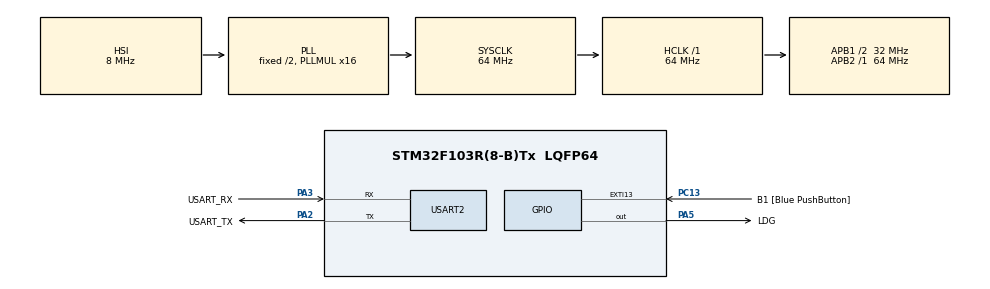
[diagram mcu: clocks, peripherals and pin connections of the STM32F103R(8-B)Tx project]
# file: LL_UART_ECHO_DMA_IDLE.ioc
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Mcu.Family=STM32F1
PC15-OSC32_OUT.Mode=LSE-External-Oscillator
NVIC.DMA1_Channel6_IRQn=true\:0\:0\:false\:false\:true\:false\:true
PA2.GPIO_PuPd=GPIO_NOPULL
Dma.USART2_TX.1.Priority=DMA_PRIORITY_LOW
PD1-OSC_OUT.Mode=HSE-External-Clock-Source
Dma.USART2_TX.1.MemInc=DMA_MINC_ENABLE
PA14.GPIO_Label=TCK
PA3.GPIO_PuPd=GPIO_NOPULL
PA2.GPIO_Speed=GPIO_SPEED_FREQ_LOW
Dma.USART2_RX.0.Direction=DMA_PERIPH_TO_MEMORY
PC13-TAMPER-RTC.Signal=GPXTI13
PD0-OSC_IN.Signal=RCC_OSC_IN
RCC.APB1CLKDivider=RCC_HCLK_DIV2
PC14-OSC32_IN.Signal=RCC_OSC32_IN
PA3.GPIO_Speed=GPIO_SPEED_FREQ_LOW
Dma.USART2_TX.1.PeriphDataAlignment=DMA_PDATAALIGN_BYTE
NVIC.USART2_IRQn=true\:0\:0\:false\:false\:true\:true\:true
RCC.SYSCLKSource=RCC_SYSCLKSOURCE_PLLCLK
ProjectManager.StackSize=0x400
Dma.USART2_RX.0.Mode=DMA_NORMAL
PD1-OSC_OUT.Signal=RCC_OSC_OUT
PA3.Mode=Asynchronous
PA13.Signal=SYS_JTMS-SWDIO
ProjectManager.TargetToolchain=STM32CubeIDE
Dma.USART2_RX.0.Priority=DMA_PRIORITY_LOW
PA3.GPIO_Mode=GPIO_MODE_AF_PP
Dma.USART2_RX.0.PeriphDataAlignment=DMA_PDATAALIGN_BYTE
RCC.HCLKFreq_Value=64000000
RCC.APB2TimFreq_Value=64000000
Dma.USART2_TX.1.Mode=DMA_NORMAL
RCC.USBFreq_Value=64000000
PC15-OSC32_OUT.Signal=RCC_OSC32_OUT
RCC.AHBFreq_Value=64000000
PD0-OSC_IN.Mode=HSE-External-Clock-Source
NVIC.EXTI15_10_IRQn=true\:0\:0\:false\:false\:true\:true\:true
PA5.Signal=GPIO_Output
Dma.USART2_TX.1.PeriphInc=DMA_PINC_DISABLE
board=NUCLEO-F103RB
RCC.RTCClockSelection=RCC_RTCCLKSOURCE_LSE
PC13-TAMPER-RTC.GPIO_Label=B1 [Blue PushButton]
RCC.PLLMUL=RCC_PLL_MUL16
Dma.USART2_TX.1.Direction=DMA_MEMORY_TO_PERIPH
RCC.APB2Freq_Value=64000000
Dma.USART2_RX.0.MemDataAlignment=DMA_MDATAALIGN_BYTE
PC14-OSC32_IN.Mode=LSE-External-Oscillator
PA5.GPIO_ModeDefaultOutputPP=GPIO_MODE_OUTPUT_PP
PA14.Mode=Serial_Wire
Dma.USART2_TX.1.Instance=DMA1_Channel7
PA5.GPIO_PuPd=GPIO_NOPULL
Dma.USART2_RX.0.Instance=DMA1_Channel6
PA13.Mode=Serial_Wire
Mcu.Name=STM32F103R(8-B)Tx
Dma.USART2_RX.0.MemInc=DMA_MINC_ENABLE
PA2.Signal=USART2_TX
PA13.GPIO_Label=TMS
PB3.Signal=SYS_JTDO-TRACESWO
RCC.SYSCLKFreq_VALUE=64000000
Mcu.Package=LQFP64
PA5.GPIO_Label=LDG
Dma.USART2_RX.0.PeriphInc=DMA_PINC_DISABLE
USART2.VirtualMode=VM_ASYNC
PC13-TAMPER-RTC.GPIO_PuPd=GPIO_NOPULL
PA2.GPIO_Label=USART_TX
PA14.Signal=SYS_JTCK-SWCLK
ProjectManager.HeapSize=0x200
PA5.GPIO_Speed=GPIO_SPEED_FREQ_LOW
NVIC.PriorityGroup=NVIC_PRIORITYGROUP_4
Dma.Request1=USART2_TX
RCC.APB1TimFreq_Value=64000000
PA2.Mode=Asynchronous
NVIC.DMA1_Channel7_IRQn=true\:0\:0\:false\:false\:true\:false\:true
Dma.USART2_TX.1.MemDataAlignment=DMA_MDATAALIGN_BYTE
Dma.Request0=USART2_RX
RCC.APB1Freq_Value=32000000
PA3.GPIO_Label=USART_RX
PA3.Signal=USART2_RX
PA2.GPIO_Mode=GPIO_MODE_AF_PP
PB3.GPIO_Label=SWO

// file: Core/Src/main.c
/* USER CODE BEGIN Header */
/**
  ******************************************************************************
  * @file           : main.c
  * @brief          : Main program body
  ******************************************************************************
  * @attention
  *
  * <h2><center>&copy; Copyright (c) 2021 STMicroelectronics.
  * All rights reserved.</center></h2>
  *
  * This software component is licensed by ST under BSD 3-Clause license,
  * the "License"; You may not use this file except in compliance with the
  * License. You may obtain a copy of the License at:
  *                        opensource.org/licenses/BSD-3-Clause
  *
  ******************************************************************************
  */
/* USER CODE END Header */
#include "main.h"
#include "dma.h"
#include "usart.h"
#include "gpio.h"

void SystemClock_Config(void);

int main(void)
{

  /* MCU Configuration--------------------------------------------------------*/

  /* Reset of all peripherals, Initializes the Flash interface and the Systick. */
  HAL_Init();

  /* Configure the system clock */
  SystemClock_Config();

  /* Initialize all configured peripherals */
  MX_GPIO_Init();
  MX_DMA_Init();
  MX_USART2_UART_Init();
  /* USER CODE BEGIN 2 */
  Init_LL_USART_IDLE();
  /* USER CODE END 2 */

  /* Infinite loop */
  /* USER CODE BEGIN WHILE */
  while (1)
  {
	  HAL_Delay(500);
	  HAL_GPIO_TogglePin(LDG_GPIO_Port, LDG_Pin);
	 // TUART_DMA_Trasmit(&TUART2,(uint8_t*) "EXAMPLES\n\r");

    /* USER CODE END WHILE */

  }
}

void SystemClock_Config(void)
{
  RCC_OscInitTypeDef RCC_OscInitStruct = {0};
  RCC_ClkInitTypeDef RCC_ClkInitStruct = {0};

  /** Initializes the RCC Oscillators according to the specified parameters
  * in the RCC_OscInitTypeDef structure.
  */
  RCC_OscInitStruct.OscillatorType = RCC_OSCILLATORTYPE_HSI;
  RCC_OscInitStruct.HSIState = RCC_HSI_ON;
  RCC_OscInitStruct.HSICalibrationValue = RCC_HSICALIBRATION_DEFAULT;
  RCC_OscInitStruct.PLL.PLLState = RCC_PLL_ON;
  RCC_OscInitStruct.PLL.PLLSource = RCC_PLLSOURCE_HSI_DIV2;
  RCC_OscInitStruct.PLL.PLLMUL = RCC_PLL_MUL16;
  if (HAL_RCC_OscConfig(&RCC_OscInitStruct) != HAL_OK)
  {
    Error_Handler();
  }
  /** Initializes the CPU, AHB and APB buses clocks
  */
  RCC_ClkInitStruct.ClockType = RCC_CLOCKTYPE_HCLK|RCC_CLOCKTYPE_SYSCLK
                              |RCC_CLOCKTYPE_PCLK1|RCC_CLOCKTYPE_PCLK2;
  RCC_ClkInitStruct.SYSCLKSource = RCC_SYSCLKSOURCE_PLLCLK;
  RCC_ClkInitStruct.AHBCLKDivider = RCC_SYSCLK_DIV1;
  RCC_ClkInitStruct.APB1CLKDivider = RCC_HCLK_DIV2;
  RCC_ClkInitStruct.APB2CLKDivider = RCC_HCLK_DIV1;

  if (HAL_RCC_ClockConfig(&RCC_ClkInitStruct, FLASH_LATENCY_2) != HAL_OK)
  {
    Error_Handler();
  }
}

void Error_Handler(void)
{
  __disable_irq();
  while (1)
  {
  }
}

/************************ (C) COPYRIGHT STMicroelectronics *****END OF FILE****/
